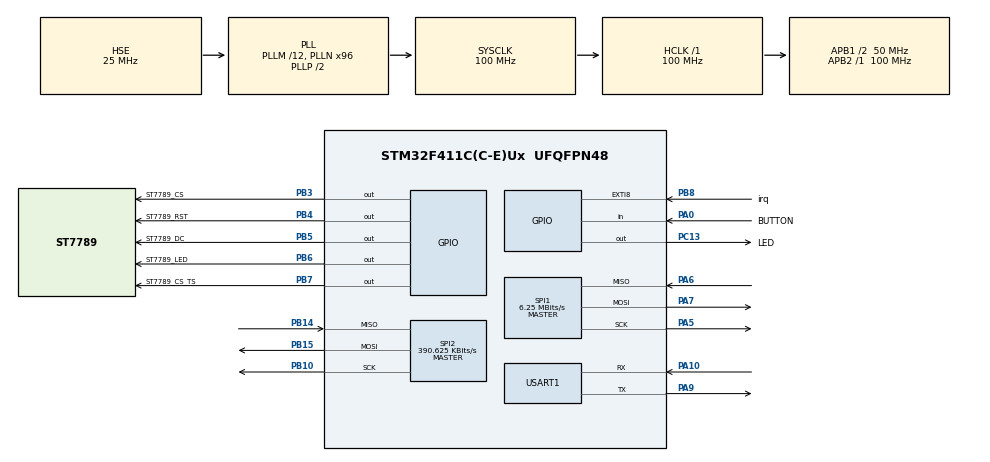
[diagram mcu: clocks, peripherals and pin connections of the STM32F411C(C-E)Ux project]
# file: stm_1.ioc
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Mcu.Family=STM32F4
Mcu.Name=STM32F411C(C-E)Ux
Mcu.Package=UFQFPN48
NVIC.PriorityGroup=NVIC_PRIORITYGROUP_4
PA0-WKUP.GPIO_Label=BUTTON
PA0-WKUP.GPIO_PuPd=GPIO_PULLUP
PA0-WKUP.Signal=GPIO_Input
PA10.Mode=Asynchronous
PA10.Signal=USART1_RX
PA13.Mode=Serial_Wire
PA13.Signal=SYS_JTMS-SWDIO
PA14.Mode=Serial_Wire
PA14.Signal=SYS_JTCK-SWCLK
PA5.Mode=Full_Duplex_Master
PA5.Signal=SPI1_SCK
PA6.Mode=Full_Duplex_Master
PA6.Signal=SPI1_MISO
PA7.Mode=Full_Duplex_Master
PA7.Signal=SPI1_MOSI
PA9.Mode=Asynchronous
PA9.Signal=USART1_TX
PB10.Mode=Full_Duplex_Master
PB10.Signal=SPI2_SCK
PB14.Mode=Full_Duplex_Master
PB14.Signal=SPI2_MISO
PB15.Mode=Full_Duplex_Master
PB15.Signal=SPI2_MOSI
PB3.GPIO_Label=ST7789_CS
PB3.GPIO_PuPd=GPIO_PULLDOWN
PB3.GPIO_Speed=GPIO_SPEED_FREQ_VERY_HIGH
PB3.PinState=GPIO_PIN_SET
PB3.Signal=GPIO_Output
PB4.GPIO_Label=ST7789_RST
PB4.GPIO_PuPd=GPIO_PULLDOWN
PB4.GPIO_Speed=GPIO_SPEED_FREQ_VERY_HIGH
PB4.PinState=GPIO_PIN_SET
PB4.Signal=GPIO_Output
PB5.GPIO_Label=ST7789_DC
PB5.GPIO_PuPd=GPIO_PULLDOWN
PB5.GPIO_Speed=GPIO_SPEED_FREQ_VERY_HIGH
PB5.PinState=GPIO_PIN_SET
PB5.Signal=GPIO_Output
PB6.GPIO_Label=ST7789_LED
PB6.GPIO_PuPd=GPIO_PULLDOWN
PB6.GPIO_Speed=GPIO_SPEED_FREQ_VERY_HIGH
PB6.PinState=GPIO_PIN_SET
PB6.Signal=GPIO_Output
PB7.GPIO_Label=ST7789_CS_TS
PB7.GPIO_PuPd=GPIO_PULLDOWN
PB7.PinState=GPIO_PIN_SET
PB7.Signal=GPIO_Output
PB8.GPIO_Label=irq
PB8.GPIO_PuPd=GPIO_PULLUP
PB8.Signal=GPXTI8
PC13-ANTI_TAMP.GPIO_Label=LED
PC13-ANTI_TAMP.PinState=GPIO_PIN_SET
PC13-ANTI_TAMP.Signal=GPIO_Output
PH0\ -\ OSC_IN.Mode=HSE-External-Oscillator
PH0\ -\ OSC_IN.Signal=RCC_OSC_IN
PH1\ -\ OSC_OUT.Mode=HSE-External-Oscillator
PH1\ -\ OSC_OUT.Signal=RCC_OSC_OUT
ProjectManager.HeapSize=0x400
ProjectManager.StackSize=0x800
ProjectManager.TargetToolchain=Makefile
RCC.48MHZClocksFreq_Value=50000000
RCC.AHBFreq_Value=100000000
RCC.APB1CLKDivider=RCC_HCLK_DIV2
RCC.APB1Freq_Value=50000000
RCC.APB1TimFreq_Value=100000000
RCC.APB2Freq_Value=100000000
RCC.APB2TimFreq_Value=100000000
RCC.CortexFreq_Value=100000000
RCC.HCLKFreq_Value=100000000
RCC.HSE_VALUE=25000000
RCC.HSI_VALUE=16000000
RCC.LSE_VALUE=32768
RCC.PLLM=12
RCC.PLLN=96
RCC.PLLSourceVirtual=RCC_PLLSOURCE_HSE
RCC.SYSCLKFreq_VALUE=100000000
RCC.SYSCLKSource=RCC_SYSCLKSOURCE_PLLCLK
RCC.VCOOutputFreq_Value=200000000
SPI1.BaudRatePrescaler=SPI_BAUDRATEPRESCALER_16
SPI1.CLKPolarity=SPI_POLARITY_HIGH
SPI1.CalculateBaudRate=6.25 MBits/s
SPI1.Direction=SPI_DIRECTION_2LINES
SPI1.Mode=SPI_MODE_MASTER
SPI1.VirtualType=VM_MASTER
SPI2.BaudRatePrescaler=SPI_BAUDRATEPRESCALER_128
SPI2.CalculateBaudRate=390.625 KBits/s
SPI2.Direction=SPI_DIRECTION_2LINES
SPI2.Mode=SPI_MODE_MASTER
SPI2.VirtualType=VM_MASTER
USART1.VirtualMode=VM_ASYNC
board=custom

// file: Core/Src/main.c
/* USER CODE BEGIN Header */
/**
 ******************************************************************************
 * @file           : main.c
 * @brief          : Main program body
 ******************************************************************************
 * @attention
 *
 * Copyright (c) 2022 STMicroelectronics.
 * All rights reserved.
 *
 * This software is licensed under terms that can be found in the LICENSE file
 * in the root directory of this software component.
 * If no LICENSE file comes with this software, it is provided AS-IS.
 *
 ******************************************************************************
 */
/* USER CODE END Header */
#include "main.h"

/* USER CODE BEGIN Includes */
#include "ili9341.h"
#include "ili9341_touch.h"
#include "fonts.h"
#include "lvgl/lvgl.h"

/* USER CODE END Includes */

SPI_HandleTypeDef hspi1;
SPI_HandleTypeDef hspi2;

UART_HandleTypeDef huart1;

void SystemClock_Config(void);
static void MX_GPIO_Init(void);
static void MX_SPI1_Init(void);
static void MX_USART1_UART_Init(void);
static void MX_SPI2_Init(void);

int main(void)
{

  /* MCU Configuration--------------------------------------------------------*/

  /* Reset of all peripherals, Initializes the Flash interface and the Systick. */
  HAL_Init();

  /* Configure the system clock */
  SystemClock_Config();

  /* Initialize all configured peripherals */
  MX_GPIO_Init();
  MX_SPI1_Init();
  MX_USART1_UART_Init();
  MX_SPI2_Init();
  /* USER CODE BEGIN 2 */

  // Initialise LVGL UI library
  lv_init();
  ILI9341_Display_Init();
  // Change the active screen's background color
  lv_obj_set_style_bg_color(lv_scr_act(), lv_color_hex(0x003a57), LV_PART_MAIN);
  lv_obj_set_style_text_color(lv_scr_act(), lv_color_hex(0xffffff), LV_PART_MAIN);

  /*Create a spinner*/
  lv_obj_t * spinner = lv_spinner_create(lv_scr_act(), 1000, 60);
  lv_obj_set_size(spinner, 64, 64);
  lv_obj_align(spinner, LV_ALIGN_BOTTOM_MID, 0, 0);
  // ILI9341_Test();

  /* USER CODE END 2 */

  /* Infinite loop */
  /* USER CODE BEGIN WHILE */
  while (1)
  {
    lv_timer_handler();
    HAL_Delay(5);
    /* USER CODE END WHILE */

  }
}

void SystemClock_Config(void)
{
  RCC_OscInitTypeDef RCC_OscInitStruct = {0};
  RCC_ClkInitTypeDef RCC_ClkInitStruct = {0};

  /** Configure the main internal regulator output voltage
  */
  __HAL_RCC_PWR_CLK_ENABLE();
  __HAL_PWR_VOLTAGESCALING_CONFIG(PWR_REGULATOR_VOLTAGE_SCALE1);

  /** Initializes the RCC Oscillators according to the specified parameters
  * in the RCC_OscInitTypeDef structure.
  */
  RCC_OscInitStruct.OscillatorType = RCC_OSCILLATORTYPE_HSE;
  RCC_OscInitStruct.HSEState = RCC_HSE_ON;
  RCC_OscInitStruct.PLL.PLLState = RCC_PLL_ON;
  RCC_OscInitStruct.PLL.PLLSource = RCC_PLLSOURCE_HSE;
  RCC_OscInitStruct.PLL.PLLM = 12;
  RCC_OscInitStruct.PLL.PLLN = 96;
  RCC_OscInitStruct.PLL.PLLP = RCC_PLLP_DIV2;
  RCC_OscInitStruct.PLL.PLLQ = 4;
  if (HAL_RCC_OscConfig(&RCC_OscInitStruct) != HAL_OK)
  {
    Error_Handler();
  }

  /** Initializes the CPU, AHB and APB buses clocks
  */
  RCC_ClkInitStruct.ClockType = RCC_CLOCKTYPE_HCLK|RCC_CLOCKTYPE_SYSCLK
                              |RCC_CLOCKTYPE_PCLK1|RCC_CLOCKTYPE_PCLK2;
  RCC_ClkInitStruct.SYSCLKSource = RCC_SYSCLKSOURCE_PLLCLK;
  RCC_ClkInitStruct.AHBCLKDivider = RCC_SYSCLK_DIV1;
  RCC_ClkInitStruct.APB1CLKDivider = RCC_HCLK_DIV2;
  RCC_ClkInitStruct.APB2CLKDivider = RCC_HCLK_DIV1;

  if (HAL_RCC_ClockConfig(&RCC_ClkInitStruct, FLASH_LATENCY_3) != HAL_OK)
  {
    Error_Handler();
  }
}

static void MX_SPI1_Init(void)
{

  /* SPI1 parameter configuration*/
  hspi1.Instance = SPI1;
  hspi1.Init.Mode = SPI_MODE_MASTER;
  hspi1.Init.Direction = SPI_DIRECTION_2LINES;
  hspi1.Init.DataSize = SPI_DATASIZE_8BIT;
  hspi1.Init.CLKPolarity = SPI_POLARITY_HIGH;
  hspi1.Init.CLKPhase = SPI_PHASE_1EDGE;
  hspi1.Init.NSS = SPI_NSS_SOFT;
  hspi1.Init.BaudRatePrescaler = SPI_BAUDRATEPRESCALER_16;
  hspi1.Init.FirstBit = SPI_FIRSTBIT_MSB;
  hspi1.Init.TIMode = SPI_TIMODE_DISABLE;
  hspi1.Init.CRCCalculation = SPI_CRCCALCULATION_DISABLE;
  hspi1.Init.CRCPolynomial = 10;
  if (HAL_SPI_Init(&hspi1) != HAL_OK)
  {
    Error_Handler();
  }

}

static void MX_SPI2_Init(void)
{

  /* SPI2 parameter configuration*/
  hspi2.Instance = SPI2;
  hspi2.Init.Mode = SPI_MODE_MASTER;
  hspi2.Init.Direction = SPI_DIRECTION_2LINES;
  hspi2.Init.DataSize = SPI_DATASIZE_8BIT;
  hspi2.Init.CLKPolarity = SPI_POLARITY_LOW;
  hspi2.Init.CLKPhase = SPI_PHASE_1EDGE;
  hspi2.Init.NSS = SPI_NSS_SOFT;
  hspi2.Init.BaudRatePrescaler = SPI_BAUDRATEPRESCALER_128;
  hspi2.Init.FirstBit = SPI_FIRSTBIT_MSB;
  hspi2.Init.TIMode = SPI_TIMODE_DISABLE;
  hspi2.Init.CRCCalculation = SPI_CRCCALCULATION_DISABLE;
  hspi2.Init.CRCPolynomial = 10;
  if (HAL_SPI_Init(&hspi2) != HAL_OK)
  {
    Error_Handler();
  }

}

static void MX_USART1_UART_Init(void)
{

  huart1.Instance = USART1;
  huart1.Init.BaudRate = 115200;
  huart1.Init.WordLength = UART_WORDLENGTH_8B;
  huart1.Init.StopBits = UART_STOPBITS_1;
  huart1.Init.Parity = UART_PARITY_NONE;
  huart1.Init.Mode = UART_MODE_TX_RX;
  huart1.Init.HwFlowCtl = UART_HWCONTROL_NONE;
  huart1.Init.OverSampling = UART_OVERSAMPLING_16;
  if (HAL_UART_Init(&huart1) != HAL_OK)
  {
    Error_Handler();
  }

}

static void MX_GPIO_Init(void)
{
  GPIO_InitTypeDef GPIO_InitStruct = {0};

  /* GPIO Ports Clock Enable */
  __HAL_RCC_GPIOC_CLK_ENABLE();
  __HAL_RCC_GPIOH_CLK_ENABLE();
  __HAL_RCC_GPIOA_CLK_ENABLE();
  __HAL_RCC_GPIOB_CLK_ENABLE();

  /*Configure GPIO pin Output Level */
  HAL_GPIO_WritePin(LED_GPIO_Port, LED_Pin, GPIO_PIN_SET);

  /*Configure GPIO pin Output Level */
  HAL_GPIO_WritePin(GPIOB, ST7789_CS_Pin|ST7789_RST_Pin|ST7789_DC_Pin|ST7789_LED_Pin
                          |ST7789_CS_TS_Pin, GPIO_PIN_SET);

  /*Configure GPIO pin : LED_Pin */
  GPIO_InitStruct.Pin = LED_Pin;
  GPIO_InitStruct.Mode = GPIO_MODE_OUTPUT_PP;
  GPIO_InitStruct.Pull = GPIO_NOPULL;
  GPIO_InitStruct.Speed = GPIO_SPEED_FREQ_LOW;
  HAL_GPIO_Init(LED_GPIO_Port, &GPIO_InitStruct);

  /*Configure GPIO pin : BUTTON_Pin */
  GPIO_InitStruct.Pin = BUTTON_Pin;
  GPIO_InitStruct.Mode = GPIO_MODE_INPUT;
  GPIO_InitStruct.Pull = GPIO_PULLUP;
  HAL_GPIO_Init(BUTTON_GPIO_Port, &GPIO_InitStruct);

  /*Configure GPIO pins : ST7789_CS_Pin ST7789_RST_Pin ST7789_DC_Pin ST7789_LED_Pin */
  GPIO_InitStruct.Pin = ST7789_CS_Pin|ST7789_RST_Pin|ST7789_DC_Pin|ST7789_LED_Pin;
  GPIO_InitStruct.Mode = GPIO_MODE_OUTPUT_PP;
  GPIO_InitStruct.Pull = GPIO_PULLDOWN;
  GPIO_InitStruct.Speed = GPIO_SPEED_FREQ_VERY_HIGH;
  HAL_GPIO_Init(GPIOB, &GPIO_InitStruct);

  /*Configure GPIO pin : ST7789_CS_TS_Pin */
  GPIO_InitStruct.Pin = ST7789_CS_TS_Pin;
  GPIO_InitStruct.Mode = GPIO_MODE_OUTPUT_PP;
  GPIO_InitStruct.Pull = GPIO_PULLDOWN;
  GPIO_InitStruct.Speed = GPIO_SPEED_FREQ_LOW;
  HAL_GPIO_Init(ST7789_CS_TS_GPIO_Port, &GPIO_InitStruct);

  /*Configure GPIO pin : irq_Pin */
  GPIO_InitStruct.Pin = irq_Pin;
  GPIO_InitStruct.Mode = GPIO_MODE_IT_RISING;
  GPIO_InitStruct.Pull = GPIO_PULLUP;
  HAL_GPIO_Init(irq_GPIO_Port, &GPIO_InitStruct);

}

void Error_Handler(void)
{
  __disable_irq();
  while (1)
  {
  }
}
